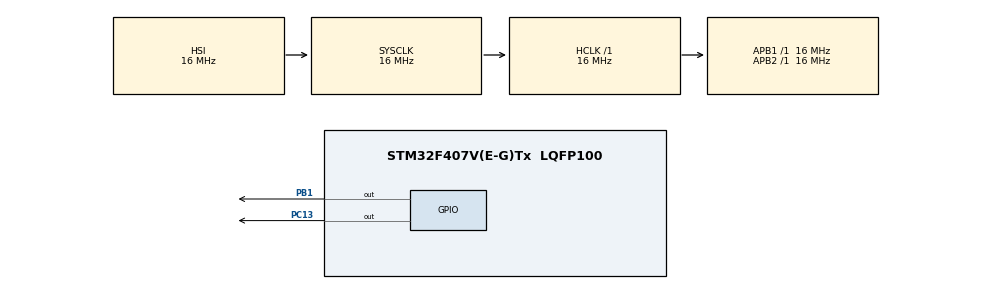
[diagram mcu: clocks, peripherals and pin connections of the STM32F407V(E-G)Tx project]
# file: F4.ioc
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FREERTOS.Tasks01=LED1_Task,0,128,LED1,Default,NULL,Dynamic,NULL,NULL;LED2_Task,-3,128,LED2,Default,NULL,Dynamic,NULL,NULL
Mcu.Family=STM32F4
Mcu.Name=STM32F407V(E-G)Tx
Mcu.Package=LQFP100
NVIC.PriorityGroup=NVIC_PRIORITYGROUP_4
PA13.Mode=Serial_Wire
PA13.Signal=SYS_JTMS-SWDIO
PA14.Mode=Serial_Wire
PA14.Signal=SYS_JTCK-SWCLK
PB1.GPIO_ModeDefaultOutputPP=GPIO_MODE_OUTPUT_PP
PB1.GPIO_PuPd=GPIO_PULLUP
PB1.PinState=GPIO_PIN_SET
PB1.Signal=GPIO_Output
PC13-ANTI_TAMP.GPIO_PuPd=GPIO_PULLUP
PC13-ANTI_TAMP.PinState=GPIO_PIN_SET
PC13-ANTI_TAMP.Signal=GPIO_Output
PC14-OSC32_IN.Mode=LSE-External-Oscillator
PC14-OSC32_IN.Signal=RCC_OSC32_IN
PC15-OSC32_OUT.Mode=LSE-External-Oscillator
PC15-OSC32_OUT.Signal=RCC_OSC32_OUT
PH0-OSC_IN.Mode=HSE-External-Oscillator
PH0-OSC_IN.Signal=RCC_OSC_IN
PH1-OSC_OUT.Mode=HSE-External-Oscillator
PH1-OSC_OUT.Signal=RCC_OSC_OUT
ProjectManager.HeapSize=0x200
ProjectManager.StackSize=0x400
ProjectManager.TargetToolchain=STM32CubeIDE
RCC.AHBFreq_Value=16000000
RCC.APB1Freq_Value=16000000
RCC.APB2Freq_Value=16000000
RCC.CortexFreq_Value=16000000
RCC.HSE_VALUE=25000000
RCC.HSI_VALUE=16000000
RCC.SYSCLKFreq_VALUE=16000000
RCC.VCOOutputFreq_Value=192000000
VP_FREERTOS_VS_CMSIS_V1.Mode=CMSIS_V1
board=custom

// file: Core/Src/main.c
/* USER CODE BEGIN Header */
/**
  ******************************************************************************
  * @file           : main.c
  * @brief          : Main program body
  ******************************************************************************
  * @attention
  *
  * Copyright (c) 2022 STMicroelectronics.
  * All rights reserved.
  *
  * This software is licensed under terms that can be found in the LICENSE file
  * in the root directory of this software component.
  * If no LICENSE file comes with this software, it is provided AS-IS.
  *
  ******************************************************************************
  */
/* USER CODE END Header */
#include "main.h"
#include "cmsis_os.h"

osThreadId LED1_TaskHandle;
osThreadId LED2_TaskHandle;
osThreadId App_TaskHandle;
/* USER CODE BEGIN PV */

//¿ÕÏÐÈÎÎñÈÎÎñ¶ÑÕ»
static StackType_t IdleTaskStack[configMINIMAL_STACK_SIZE];
//¿ÕÏÐÈÎÎñ¿ØÖÆ¿é
static StaticTask_t IdleTaskTCB;

//¶¨Ê±Æ÷·þÎñÈÎÎñ¶ÑÕ»
static StackType_t TimerTaskStack[configTIMER_TASK_STACK_DEPTH];
//¶¨Ê±Æ÷·þÎñÈÎÎñ¿ØÖÆ¿é
static StaticTask_t TimerTaskTCB;

/* USER CODE END PV */

void SystemClock_Config(void);
static void MX_GPIO_Init(void);
void LED1(void const * argument);
void LED2(void const * argument);
void App_Start(void const * argument);

static StackType_t AppStartStack[128];
StaticTask_t AppTaskTCB;

int main(void)
{

  /* MCU Configuration--------------------------------------------------------*/

  /* Reset of all peripherals, Initializes the Flash interface and the Systick. */
  HAL_Init();

  /* Configure the system clock */
  SystemClock_Config();

  /* Initialize all configured peripherals */
  MX_GPIO_Init();

  /* Create the thread(s) */
  /* definition and creation of LED1_Task */

  App_TaskHandle=xTaskCreateStatic(App_Start,
		  "AppTaskCreate", 128,
		  NULL, 3, AppStartStack, &AppTaskTCB);
  if(NULL!=App_TaskHandle)
  {
	  printf("ok!\n");
  }

  /* Start scheduler */
  //osKernelStart();
  vTaskStartScheduler();

  /* We should never get here as control is now taken by the scheduler */
  /* Infinite loop */
  while (1)
  {

  }
}

void SystemClock_Config(void)
{
  RCC_OscInitTypeDef RCC_OscInitStruct = {0};
  RCC_ClkInitTypeDef RCC_ClkInitStruct = {0};

  /** Configure the main internal regulator output voltage
  */
  __HAL_RCC_PWR_CLK_ENABLE();
  __HAL_PWR_VOLTAGESCALING_CONFIG(PWR_REGULATOR_VOLTAGE_SCALE1);
  /** Initializes the RCC Oscillators according to the specified parameters
  * in the RCC_OscInitTypeDef structure.
  */
  RCC_OscInitStruct.OscillatorType = RCC_OSCILLATORTYPE_HSI;
  RCC_OscInitStruct.HSIState = RCC_HSI_ON;
  RCC_OscInitStruct.HSICalibrationValue = RCC_HSICALIBRATION_DEFAULT;
  RCC_OscInitStruct.PLL.PLLState = RCC_PLL_NONE;
  if (HAL_RCC_OscConfig(&RCC_OscInitStruct) != HAL_OK)
  {
    Error_Handler();
  }
  /** Initializes the CPU, AHB and APB buses clocks
  */
  RCC_ClkInitStruct.ClockType = RCC_CLOCKTYPE_HCLK|RCC_CLOCKTYPE_SYSCLK
                              |RCC_CLOCKTYPE_PCLK1|RCC_CLOCKTYPE_PCLK2;
  RCC_ClkInitStruct.SYSCLKSource = RCC_SYSCLKSOURCE_HSI;
  RCC_ClkInitStruct.AHBCLKDivider = RCC_SYSCLK_DIV1;
  RCC_ClkInitStruct.APB1CLKDivider = RCC_HCLK_DIV1;
  RCC_ClkInitStruct.APB2CLKDivider = RCC_HCLK_DIV1;

  if (HAL_RCC_ClockConfig(&RCC_ClkInitStruct, FLASH_LATENCY_0) != HAL_OK)
  {
    Error_Handler();
  }
}

static void MX_GPIO_Init(void)
{
  GPIO_InitTypeDef GPIO_InitStruct = {0};

  /* GPIO Ports Clock Enable */
  __HAL_RCC_GPIOC_CLK_ENABLE();
  __HAL_RCC_GPIOH_CLK_ENABLE();
  __HAL_RCC_GPIOB_CLK_ENABLE();
  __HAL_RCC_GPIOA_CLK_ENABLE();

  /*Configure GPIO pin Output Level */
  HAL_GPIO_WritePin(GPIOC, GPIO_PIN_13, GPIO_PIN_SET);

  /*Configure GPIO pin Output Level */
  HAL_GPIO_WritePin(GPIOB, GPIO_PIN_1, GPIO_PIN_SET);

  /*Configure GPIO pin : PC13 */
  GPIO_InitStruct.Pin = GPIO_PIN_13;
  GPIO_InitStruct.Mode = GPIO_MODE_OUTPUT_PP;
  GPIO_InitStruct.Pull = GPIO_PULLUP;
  GPIO_InitStruct.Speed = GPIO_SPEED_FREQ_LOW;
  HAL_GPIO_Init(GPIOC, &GPIO_InitStruct);

  /*Configure GPIO pin : PB1 */
  GPIO_InitStruct.Pin = GPIO_PIN_1;
  GPIO_InitStruct.Mode = GPIO_MODE_OUTPUT_PP;
  GPIO_InitStruct.Pull = GPIO_PULLUP;
  GPIO_InitStruct.Speed = GPIO_SPEED_FREQ_LOW;
  HAL_GPIO_Init(GPIOB, &GPIO_InitStruct);

}

void LED1(void const * argument)
{
  /* USER CODE BEGIN 5 */
  /* Infinite loop */
  for(;;)
  {
    osDelay(100);
    HAL_GPIO_TogglePin(GPIOB, GPIO_PIN_1);
  }
  /* USER CODE END 5 */
}

void LED2(void const * argument)
{
  /* USER CODE BEGIN LED2 */
  /* Infinite loop */
  for(;;)
  {
    osDelay(1000);
    HAL_GPIO_TogglePin(GPIOC, GPIO_PIN_13);
  }
  /* USER CODE END LED2 */
}

void App_Start(void const * argument)
{
	taskENTER_CRITICAL();

	  /* definition and creation of LED1_Task */
	osThreadDef(LED1_Task, LED1, osPriorityNormal, 0, 128);
	LED1_TaskHandle = osThreadCreate(osThread(LED1_Task), NULL);
	if(NULL!=LED1_TaskHandle)
	{
		//printf("LED1任务创建成功!\n");
	}

	 /* definition and creation of LED2_Task */
	osThreadDef(LED2_Task, LED2, osPriorityIdle, 0, 128);
	LED2_TaskHandle = osThreadCreate(osThread(LED2_Task), NULL);
	if(NULL!=LED2_TaskHandle)
	{
		//printf("LED2任务创建成功!\n");
	}

    vTaskDelete(App_TaskHandle);
    taskEXIT_CRITICAL();
}
void Error_Handler(void)
{
  __disable_irq();
  while (1)
  {
  }
}
